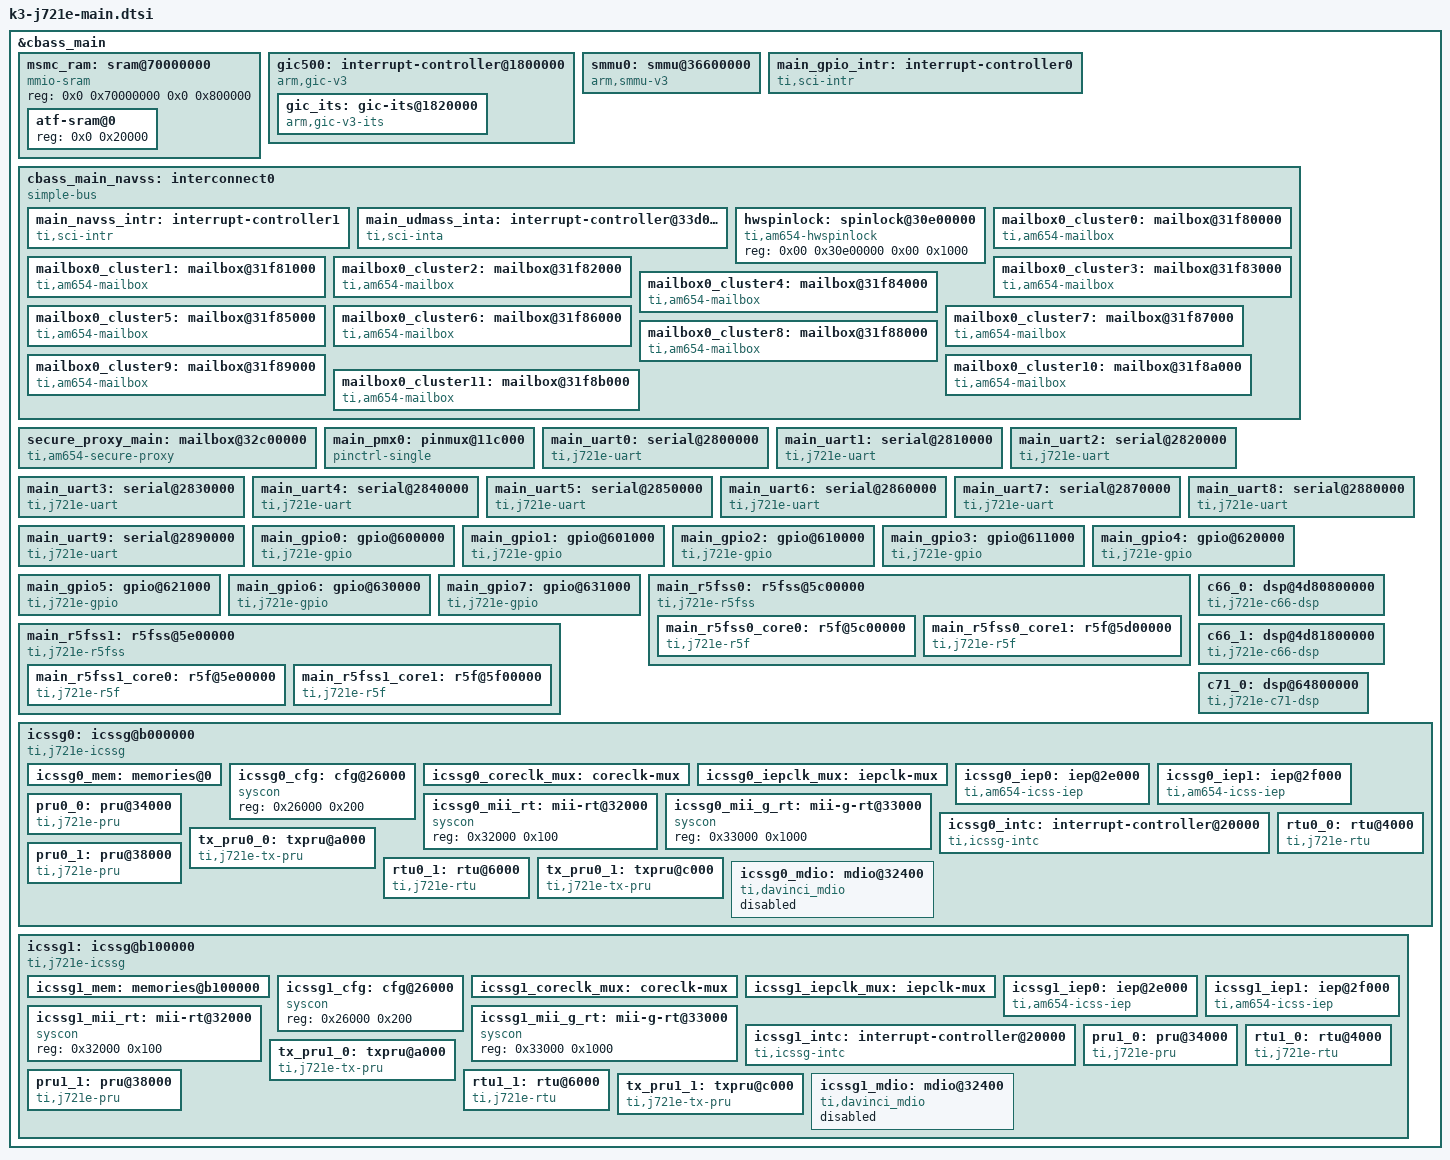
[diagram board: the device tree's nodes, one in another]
// SPDX-License-Identifier: GPL-2.0
/*
 * Device Tree Source for J721E SoC Family Main Domain peripherals
 *
 * Copyright (C) 2016-2019 Texas Instruments Incorporated - http://www.ti.com/
 */

&cbass_main {
	msmc_ram: sram@70000000 {
		compatible = "mmio-sram";
		reg = <0x0 0x70000000 0x0 0x800000>;
		#address-cells = <1>;
		#size-cells = <1>;
		ranges = <0x0 0x0 0x70000000 0x800000>;

		atf-sram@0 {
			reg = <0x0 0x20000>;
		};
	};

	gic500: interrupt-controller@1800000 {
		compatible = "arm,gic-v3";
		#address-cells = <2>;
		#size-cells = <2>;
		ranges;
		#interrupt-cells = <3>;
		interrupt-controller;
		reg = <0x00 0x01800000 0x00 0x10000>,	/* GICD */
		      <0x00 0x01900000 0x00 0x100000>;	/* GICR */

		/* vcpumntirq: virtual CPU interface maintenance interrupt */
		interrupts = <GIC_PPI 9 IRQ_TYPE_LEVEL_HIGH>;

		gic_its: gic-its@1820000 {
			compatible = "arm,gic-v3-its";
			reg = <0x00 0x01820000 0x00 0x10000>;
			socionext,synquacer-pre-its = <0x1000000 0x400000>;
			msi-controller;
			#msi-cells = <1>;
		};
	};

	smmu0: smmu@36600000 {
		compatible = "arm,smmu-v3";
		reg = <0x0 0x36600000 0x0 0x100000>;
		interrupt-parent = <&gic500>;
		interrupts = <GIC_SPI 772 IRQ_TYPE_EDGE_RISING>,
			     <GIC_SPI 768 IRQ_TYPE_EDGE_RISING>;
		interrupt-names = "eventq", "gerror";
		#iommu-cells = <1>;
	};

	main_gpio_intr: interrupt-controller0 {
		compatible = "ti,sci-intr";
		ti,intr-trigger-type = <1>;
		interrupt-controller;
		interrupt-parent = <&gic500>;
		#interrupt-cells = <2>;
		ti,sci = <&dmsc>;
		ti,sci-dst-id = <14>;
		ti,sci-rm-range-girq = <0x1>;
	};

	cbass_main_navss: interconnect0 {
		compatible = "simple-bus";
		#address-cells = <2>;
		#size-cells = <2>;
		ranges;

		main_navss_intr: interrupt-controller1 {
			compatible = "ti,sci-intr";
			ti,intr-trigger-type = <4>;
			interrupt-controller;
			interrupt-parent = <&gic500>;
			#interrupt-cells = <2>;
			ti,sci = <&dmsc>;
			ti,sci-dst-id = <14>;
			ti,sci-rm-range-girq = <0>, <2>;
		};

		main_udmass_inta: interrupt-controller@33d00000 {
			compatible = "ti,sci-inta";
			reg = <0x0 0x33d00000 0x0 0x100000>;
			interrupt-controller;
			interrupt-parent = <&main_navss_intr>;
			msi-controller;
			ti,sci = <&dmsc>;
			ti,sci-dev-id = <209>;
			ti,sci-rm-range-vint = <0xa>;
			ti,sci-rm-range-global-event = <0xd>;
		};

		hwspinlock: spinlock@30e00000 {
			compatible = "ti,am654-hwspinlock";
			reg = <0x00 0x30e00000 0x00 0x1000>;
			#hwlock-cells = <1>;
		};

		mailbox0_cluster0: mailbox@31f80000 {
			compatible = "ti,am654-mailbox";
			reg = <0x00 0x31f80000 0x00 0x200>;
			#mbox-cells = <1>;
			ti,mbox-num-users = <4>;
			ti,mbox-num-fifos = <16>;
			interrupt-parent = <&main_navss_intr>;
		};

		mailbox0_cluster1: mailbox@31f81000 {
			compatible = "ti,am654-mailbox";
			reg = <0x00 0x31f81000 0x00 0x200>;
			#mbox-cells = <1>;
			ti,mbox-num-users = <4>;
			ti,mbox-num-fifos = <16>;
			interrupt-parent = <&main_navss_intr>;
		};

		mailbox0_cluster2: mailbox@31f82000 {
			compatible = "ti,am654-mailbox";
			reg = <0x00 0x31f82000 0x00 0x200>;
			#mbox-cells = <1>;
			ti,mbox-num-users = <4>;
			ti,mbox-num-fifos = <16>;
			interrupt-parent = <&main_navss_intr>;
		};

		mailbox0_cluster3: mailbox@31f83000 {
			compatible = "ti,am654-mailbox";
			reg = <0x00 0x31f83000 0x00 0x200>;
			#mbox-cells = <1>;
			ti,mbox-num-users = <4>;
			ti,mbox-num-fifos = <16>;
			interrupt-parent = <&main_navss_intr>;
		};

		mailbox0_cluster4: mailbox@31f84000 {
			compatible = "ti,am654-mailbox";
			reg = <0x00 0x31f84000 0x00 0x200>;
			#mbox-cells = <1>;
			ti,mbox-num-users = <4>;
			ti,mbox-num-fifos = <16>;
			interrupt-parent = <&main_navss_intr>;
		};

		mailbox0_cluster5: mailbox@31f85000 {
			compatible = "ti,am654-mailbox";
			reg = <0x00 0x31f85000 0x00 0x200>;
			#mbox-cells = <1>;
			ti,mbox-num-users = <4>;
			ti,mbox-num-fifos = <16>;
			interrupt-parent = <&main_navss_intr>;
		};

		mailbox0_cluster6: mailbox@31f86000 {
			compatible = "ti,am654-mailbox";
			reg = <0x00 0x31f86000 0x00 0x200>;
			#mbox-cells = <1>;
			ti,mbox-num-users = <4>;
			ti,mbox-num-fifos = <16>;
			interrupt-parent = <&main_navss_intr>;
		};

		mailbox0_cluster7: mailbox@31f87000 {
			compatible = "ti,am654-mailbox";
			reg = <0x00 0x31f87000 0x00 0x200>;
			#mbox-cells = <1>;
			ti,mbox-num-users = <4>;
			ti,mbox-num-fifos = <16>;
			interrupt-parent = <&main_navss_intr>;
		};

		mailbox0_cluster8: mailbox@31f88000 {
			compatible = "ti,am654-mailbox";
			reg = <0x00 0x31f88000 0x00 0x200>;
			#mbox-cells = <1>;
			ti,mbox-num-users = <4>;
			ti,mbox-num-fifos = <16>;
			interrupt-parent = <&main_navss_intr>;
		};

		mailbox0_cluster9: mailbox@31f89000 {
			compatible = "ti,am654-mailbox";
			reg = <0x00 0x31f89000 0x00 0x200>;
			#mbox-cells = <1>;
			ti,mbox-num-users = <4>;
			ti,mbox-num-fifos = <16>;
			interrupt-parent = <&main_navss_intr>;
		};

		mailbox0_cluster10: mailbox@31f8a000 {
			compatible = "ti,am654-mailbox";
			reg = <0x00 0x31f8a000 0x00 0x200>;
			#mbox-cells = <1>;
			ti,mbox-num-users = <4>;
			ti,mbox-num-fifos = <16>;
			interrupt-parent = <&main_navss_intr>;
		};

		mailbox0_cluster11: mailbox@31f8b000 {
			compatible = "ti,am654-mailbox";
			reg = <0x00 0x31f8b000 0x00 0x200>;
			#mbox-cells = <1>;
			ti,mbox-num-users = <4>;
			ti,mbox-num-fifos = <16>;
			interrupt-parent = <&main_navss_intr>;
		};
	};

	secure_proxy_main: mailbox@32c00000 {
		compatible = "ti,am654-secure-proxy";
		#mbox-cells = <1>;
		reg-names = "target_data", "rt", "scfg";
		reg = <0x00 0x32c00000 0x00 0x100000>,
		      <0x00 0x32400000 0x00 0x100000>,
		      <0x00 0x32800000 0x00 0x100000>;
		interrupt-names = "rx_011";
		interrupts = <GIC_SPI 37 IRQ_TYPE_LEVEL_HIGH>;
	};

	main_pmx0: pinmux@11c000 {
		compatible = "pinctrl-single";
		/* Proxy 0 addressing */
		reg = <0x0 0x11c000 0x0 0x2b4>;
		#pinctrl-cells = <1>;
		pinctrl-single,register-width = <32>;
		pinctrl-single,function-mask = <0xffffffff>;
	};

	main_uart0: serial@2800000 {
		compatible = "ti,j721e-uart", "ti,am654-uart";
		reg = <0x00 0x02800000 0x00 0x100>;
		reg-shift = <2>;
		reg-io-width = <4>;
		interrupts = <GIC_SPI 192 IRQ_TYPE_LEVEL_HIGH>;
		clock-frequency = <48000000>;
		current-speed = <115200>;
		power-domains = <&k3_pds 146 TI_SCI_PD_EXCLUSIVE>;
		clocks = <&k3_clks 146 0>;
		clock-names = "fclk";
	};

	main_uart1: serial@2810000 {
		compatible = "ti,j721e-uart", "ti,am654-uart";
		reg = <0x00 0x02810000 0x00 0x100>;
		reg-shift = <2>;
		reg-io-width = <4>;
		interrupts = <GIC_SPI 193 IRQ_TYPE_LEVEL_HIGH>;
		clock-frequency = <48000000>;
		current-speed = <115200>;
		power-domains = <&k3_pds 278 TI_SCI_PD_EXCLUSIVE>;
		clocks = <&k3_clks 278 0>;
		clock-names = "fclk";
	};

	main_uart2: serial@2820000 {
		compatible = "ti,j721e-uart", "ti,am654-uart";
		reg = <0x00 0x02820000 0x00 0x100>;
		reg-shift = <2>;
		reg-io-width = <4>;
		interrupts = <GIC_SPI 194 IRQ_TYPE_LEVEL_HIGH>;
		clock-frequency = <48000000>;
		current-speed = <115200>;
		power-domains = <&k3_pds 279 TI_SCI_PD_EXCLUSIVE>;
		clocks = <&k3_clks 279 0>;
		clock-names = "fclk";
	};

	main_uart3: serial@2830000 {
		compatible = "ti,j721e-uart", "ti,am654-uart";
		reg = <0x00 0x02830000 0x00 0x100>;
		reg-shift = <2>;
		reg-io-width = <4>;
		interrupts = <GIC_SPI 195 IRQ_TYPE_LEVEL_HIGH>;
		clock-frequency = <48000000>;
		current-speed = <115200>;
		power-domains = <&k3_pds 280 TI_SCI_PD_EXCLUSIVE>;
		clocks = <&k3_clks 280 0>;
		clock-names = "fclk";
	};

	main_uart4: serial@2840000 {
		compatible = "ti,j721e-uart", "ti,am654-uart";
		reg = <0x00 0x02840000 0x00 0x100>;
		reg-shift = <2>;
		reg-io-width = <4>;
		interrupts = <GIC_SPI 196 IRQ_TYPE_LEVEL_HIGH>;
		clock-frequency = <48000000>;
		current-speed = <115200>;
		power-domains = <&k3_pds 281 TI_SCI_PD_EXCLUSIVE>;
		clocks = <&k3_clks 281 0>;
		clock-names = "fclk";
	};

	main_uart5: serial@2850000 {
		compatible = "ti,j721e-uart", "ti,am654-uart";
		reg = <0x00 0x02850000 0x00 0x100>;
		reg-shift = <2>;
		reg-io-width = <4>;
		interrupts = <GIC_SPI 197 IRQ_TYPE_LEVEL_HIGH>;
		clock-frequency = <48000000>;
		current-speed = <115200>;
		power-domains = <&k3_pds 282 TI_SCI_PD_EXCLUSIVE>;
		clocks = <&k3_clks 282 0>;
		clock-names = "fclk";
	};

	main_uart6: serial@2860000 {
		compatible = "ti,j721e-uart", "ti,am654-uart";
		reg = <0x00 0x02860000 0x00 0x100>;
		reg-shift = <2>;
		reg-io-width = <4>;
		interrupts = <GIC_SPI 198 IRQ_TYPE_LEVEL_HIGH>;
		clock-frequency = <48000000>;
		current-speed = <115200>;
		power-domains = <&k3_pds 283 TI_SCI_PD_EXCLUSIVE>;
		clocks = <&k3_clks 283 0>;
		clock-names = "fclk";
	};

	main_uart7: serial@2870000 {
		compatible = "ti,j721e-uart", "ti,am654-uart";
		reg = <0x00 0x02870000 0x00 0x100>;
		reg-shift = <2>;
		reg-io-width = <4>;
		interrupts = <GIC_SPI 199 IRQ_TYPE_LEVEL_HIGH>;
		clock-frequency = <48000000>;
		current-speed = <115200>;
		power-domains = <&k3_pds 284 TI_SCI_PD_EXCLUSIVE>;
		clocks = <&k3_clks 284 0>;
		clock-names = "fclk";
	};

	main_uart8: serial@2880000 {
		compatible = "ti,j721e-uart", "ti,am654-uart";
		reg = <0x00 0x02880000 0x00 0x100>;
		reg-shift = <2>;
		reg-io-width = <4>;
		interrupts = <GIC_SPI 248 IRQ_TYPE_LEVEL_HIGH>;
		clock-frequency = <48000000>;
		current-speed = <115200>;
		power-domains = <&k3_pds 285 TI_SCI_PD_EXCLUSIVE>;
		clocks = <&k3_clks 285 0>;
		clock-names = "fclk";
	};

	main_uart9: serial@2890000 {
		compatible = "ti,j721e-uart", "ti,am654-uart";
		reg = <0x00 0x02890000 0x00 0x100>;
		reg-shift = <2>;
		reg-io-width = <4>;
		interrupts = <GIC_SPI 249 IRQ_TYPE_LEVEL_HIGH>;
		clock-frequency = <48000000>;
		current-speed = <115200>;
		power-domains = <&k3_pds 286 TI_SCI_PD_EXCLUSIVE>;
		clocks = <&k3_clks 286 0>;
		clock-names = "fclk";
	};

	main_gpio0: gpio@600000 {
		compatible = "ti,j721e-gpio", "ti,keystone-gpio";
		reg = <0x0 0x00600000 0x0 0x100>;
		gpio-controller;
		#gpio-cells = <2>;
		interrupt-parent = <&main_gpio_intr>;
		interrupts = <105 0>, <105 1>, <105 2>, <105 3>,
			     <105 4>, <105 5>, <105 6>, <105 7>;
		interrupt-controller;
		#interrupt-cells = <2>;
		ti,ngpio = <128>;
		ti,davinci-gpio-unbanked = <0>;
		power-domains = <&k3_pds 105 TI_SCI_PD_EXCLUSIVE>;
		clocks = <&k3_clks 105 0>;
		clock-names = "gpio";
	};

	main_gpio1: gpio@601000 {
		compatible = "ti,j721e-gpio", "ti,keystone-gpio";
		reg = <0x0 0x00601000 0x0 0x100>;
		gpio-controller;
		#gpio-cells = <2>;
		interrupt-parent = <&main_gpio_intr>;
		interrupts = <106 0>, <106 1>, <106 2>;
		interrupt-controller;
		#interrupt-cells = <2>;
		ti,ngpio = <36>;
		ti,davinci-gpio-unbanked = <0>;
		power-domains = <&k3_pds 106 TI_SCI_PD_EXCLUSIVE>;
		clocks = <&k3_clks 106 0>;
		clock-names = "gpio";
	};

	main_gpio2: gpio@610000 {
		compatible = "ti,j721e-gpio", "ti,keystone-gpio";
		reg = <0x0 0x00610000 0x0 0x100>;
		gpio-controller;
		#gpio-cells = <2>;
		interrupt-parent = <&main_gpio_intr>;
		interrupts = <107 0>, <107 1>, <107 2>, <107 3>,
			     <107 4>, <107 5>, <107 6>, <107 7>;
		interrupt-controller;
		#interrupt-cells = <2>;
		ti,ngpio = <128>;
		ti,davinci-gpio-unbanked = <0>;
		power-domains = <&k3_pds 107 TI_SCI_PD_EXCLUSIVE>;
		clocks = <&k3_clks 107 0>;
		clock-names = "gpio";
	};

	main_gpio3: gpio@611000 {
		compatible = "ti,j721e-gpio", "ti,keystone-gpio";
		reg = <0x0 0x00611000 0x0 0x100>;
		gpio-controller;
		#gpio-cells = <2>;
		interrupt-parent = <&main_gpio_intr>;
		interrupts = <108 0>, <108 1>, <108 2>;
		interrupt-controller;
		#interrupt-cells = <2>;
		ti,ngpio = <36>;
		ti,davinci-gpio-unbanked = <0>;
		power-domains = <&k3_pds 108 TI_SCI_PD_EXCLUSIVE>;
		clocks = <&k3_clks 108 0>;
		clock-names = "gpio";
	};

	main_gpio4: gpio@620000 {
		compatible = "ti,j721e-gpio", "ti,keystone-gpio";
		reg = <0x0 0x00620000 0x0 0x100>;
		gpio-controller;
		#gpio-cells = <2>;
		interrupt-parent = <&main_gpio_intr>;
		interrupts = <109 0>, <109 1>, <109 2>, <109 3>,
			     <109 4>, <109 5>, <109 6>, <109 7>;
		interrupt-controller;
		#interrupt-cells = <2>;
		ti,ngpio = <128>;
		ti,davinci-gpio-unbanked = <0>;
		power-domains = <&k3_pds 109 TI_SCI_PD_EXCLUSIVE>;
		clocks = <&k3_clks 109 0>;
		clock-names = "gpio";
	};

	main_gpio5: gpio@621000 {
		compatible = "ti,j721e-gpio", "ti,keystone-gpio";
		reg = <0x0 0x00621000 0x0 0x100>;
		gpio-controller;
		#gpio-cells = <2>;
		interrupt-parent = <&main_gpio_intr>;
		interrupts = <110 0>, <110 1>, <110 2>;
		interrupt-controller;
		#interrupt-cells = <2>;
		ti,ngpio = <36>;
		ti,davinci-gpio-unbanked = <0>;
		power-domains = <&k3_pds 110 TI_SCI_PD_EXCLUSIVE>;
		clocks = <&k3_clks 110 0>;
		clock-names = "gpio";
	};

	main_gpio6: gpio@630000 {
		compatible = "ti,j721e-gpio", "ti,keystone-gpio";
		reg = <0x0 0x00630000 0x0 0x100>;
		gpio-controller;
		#gpio-cells = <2>;
		interrupt-parent = <&main_gpio_intr>;
		interrupts = <111 0>, <111 1>, <111 2>, <111 3>,
			     <111 4>, <111 5>, <111 6>, <111 7>;
		interrupt-controller;
		#interrupt-cells = <2>;
		ti,ngpio = <128>;
		ti,davinci-gpio-unbanked = <0>;
		power-domains = <&k3_pds 111 TI_SCI_PD_EXCLUSIVE>;
		clocks = <&k3_clks 111 0>;
		clock-names = "gpio";
	};

	main_gpio7: gpio@631000 {
		compatible = "ti,j721e-gpio", "ti,keystone-gpio";
		reg = <0x0 0x00631000 0x0 0x100>;
		gpio-controller;
		#gpio-cells = <2>;
		interrupt-parent = <&main_gpio_intr>;
		interrupts = <112 0>, <112 1>, <112 2>;
		interrupt-controller;
		#interrupt-cells = <2>;
		ti,ngpio = <36>;
		ti,davinci-gpio-unbanked = <0>;
		power-domains = <&k3_pds 112 TI_SCI_PD_EXCLUSIVE>;
		clocks = <&k3_clks 112 0>;
		clock-names = "gpio";
	};

	main_r5fss0: r5fss@5c00000 {
		compatible = "ti,j721e-r5fss";
		lockstep-mode = <0>;
		#address-cells = <1>;
		#size-cells = <1>;
		ranges = <0x5c00000 0x00 0x5c00000 0x20000>,
			 <0x5d00000 0x00 0x5d00000 0x20000>;
		power-domains = <&k3_pds 243 TI_SCI_PD_EXCLUSIVE>;

		main_r5fss0_core0: r5f@5c00000 {
			compatible = "ti,j721e-r5f";
			reg = <0x5c00000 0x00008000>,
			      <0x5c10000 0x00008000>;
			reg-names = "atcm", "btcm";
			ti,sci = <&dmsc>;
			ti,sci-dev-id = <245>;
			ti,sci-proc-ids = <0x06 0xFF>;
			resets = <&k3_reset 245 1>;
			firmware-name = "j7-main-r5f0_0-fw";
			atcm-enable = <1>;
			btcm-enable = <1>;
			loczrama = <1>;
		};

		main_r5fss0_core1: r5f@5d00000 {
			compatible = "ti,j721e-r5f";
			reg = <0x5d00000 0x00008000>,
			      <0x5d10000 0x00008000>;
			reg-names = "atcm", "btcm";
			ti,sci = <&dmsc>;
			ti,sci-dev-id = <246>;
			ti,sci-proc-ids = <0x07 0xFF>;
			resets = <&k3_reset 246 1>;
			firmware-name = "j7-main-r5f0_1-fw";
			atcm-enable = <1>;
			btcm-enable = <1>;
			loczrama = <1>;
		};
	};

	main_r5fss1: r5fss@5e00000 {
		compatible = "ti,j721e-r5fss";
		lockstep-mode = <0>;
		#address-cells = <1>;
		#size-cells = <1>;
		ranges = <0x5e00000 0x00 0x5e00000 0x20000>,
			 <0x5f00000 0x00 0x5f00000 0x20000>;
		power-domains = <&k3_pds 244 TI_SCI_PD_EXCLUSIVE>;

		main_r5fss1_core0: r5f@5e00000 {
			compatible = "ti,j721e-r5f";
			reg = <0x5e00000 0x00008000>,
			      <0x5e10000 0x00008000>;
			reg-names = "atcm", "btcm";
			ti,sci = <&dmsc>;
			ti,sci-dev-id = <247>;
			ti,sci-proc-ids = <0x08 0xFF>;
			resets = <&k3_reset 247 1>;
			firmware-name = "j7-main-r5f1_0-fw";
			atcm-enable = <1>;
			btcm-enable = <1>;
			loczrama = <1>;
		};

		main_r5fss1_core1: r5f@5f00000 {
			compatible = "ti,j721e-r5f";
			reg = <0x5f00000 0x00008000>,
			      <0x5f10000 0x00008000>;
			reg-names = "atcm", "btcm";
			ti,sci = <&dmsc>;
			ti,sci-dev-id = <248>;
			ti,sci-proc-ids = <0x09 0xFF>;
			resets = <&k3_reset 248 1>;
			firmware-name = "j7-main-r5f1_1-fw";
			atcm-enable = <1>;
			btcm-enable = <1>;
			loczrama = <1>;
		};
	};

	c66_0: dsp@4d80800000 {
		compatible = "ti,j721e-c66-dsp";
		reg = <0x4d 0x80800000 0x00 0x00048000>,
		      <0x4d 0x80e00000 0x00 0x00008000>,
		      <0x4d 0x80f00000 0x00 0x00008000>;
		reg-names = "l2sram", "l1pram", "l1dram";
		ti,sci = <&dmsc>;
		ti,sci-dev-id = <142>;
		ti,sci-proc-ids = <0x03 0xFF>;
		resets = <&k3_reset 142 1>;
		firmware-name = "j7-c66_0-fw";
	};

	c66_1: dsp@4d81800000 {
		compatible = "ti,j721e-c66-dsp";
		reg = <0x4d 0x81800000 0x00 0x00048000>,
		      <0x4d 0x81e00000 0x00 0x00008000>,
		      <0x4d 0x81f00000 0x00 0x00008000>;
		reg-names = "l2sram", "l1pram", "l1dram";
		ti,sci = <&dmsc>;
		ti,sci-dev-id = <143>;
		ti,sci-proc-ids = <0x04 0xFF>;
		resets = <&k3_reset 143 1>;
		firmware-name = "j7-c66_1-fw";
	};

	c71_0: dsp@64800000 {
		compatible = "ti,j721e-c71-dsp";
		reg = <0x00 0x64800000 0x00 0x00080000>,
		      <0x00 0x64e00000 0x00 0x0000c000>;
		reg-names = "l2sram", "l1dram";
		ti,sci = <&dmsc>;
		ti,sci-dev-id = <15>;
		ti,sci-proc-ids = <0x30 0xFF>;
		resets = <&k3_reset 15 1>;
		firmware-name = "j7-c71_0-fw";
	};

	icssg0: icssg@b000000 {
		compatible = "ti,j721e-icssg";
		reg = <0x00 0xb000000 0x00 0x80000>;
		power-domains = <&k3_pds 119 TI_SCI_PD_EXCLUSIVE>;
		#address-cells = <1>;
		#size-cells = <1>;
		ranges = <0x0 0x00 0x0b000000 0x100000>;
		dma-ranges;

		icssg0_mem: memories@0 {
			reg = <0x0 0x2000>,
			      <0x2000 0x2000>,
			      <0x10000 0x10000>;
			reg-names = "dram0", "dram1",
				    "shrdram2";
		};

		icssg0_cfg: cfg@26000 {
			compatible = "syscon";
			reg = <0x26000 0x200>;
		};

		icssg0_coreclk_mux: coreclk-mux {
			#clock-cells = <0>;
			clocks = <&k3_clks 119 24>, /* icssg0_core_clk */
				 <&k3_clks 119 1>;  /* icssg0_iclk */
			assigned-clocks = <&icssg0_coreclk_mux>;
			assigned-clock-parents = <&k3_clks 119 1>;
		};

		icssg0_iepclk_mux: iepclk-mux {
			#clock-cells = <0>;
			clocks = <&k3_clks 119 3>,	/* icssg0_iep_clk */
				 <&icssg0_coreclk_mux>;	/* core_clk */
			assigned-clocks = <&icssg0_iepclk_mux>;
			assigned-clock-parents = <&icssg0_coreclk_mux>;
		};

		icssg0_iep0: iep@2e000 {
			compatible = "ti,am654-icss-iep";
			reg = <0x2e000 0x1000>;
			clocks = <&icssg0_iepclk_mux>;
		};

		icssg0_iep1: iep@2f000 {
			compatible = "ti,am654-icss-iep";
			reg = <0x2f000 0x1000>;
			clocks = <&icssg0_iepclk_mux>;
		};

		icssg0_mii_rt: mii-rt@32000 {
			compatible = "syscon";
			reg = <0x32000 0x100>;
		};

		icssg0_mii_g_rt: mii-g-rt@33000 {
			compatible = "syscon";
			reg = <0x33000 0x1000>;
		};

		icssg0_intc: interrupt-controller@20000 {
			compatible = "ti,icssg-intc";
			reg = <0x20000 0x2000>;
			interrupt-controller;
			#interrupt-cells = <1>;
			interrupts = <GIC_SPI 254 IRQ_TYPE_LEVEL_HIGH>,
				     <GIC_SPI 255 IRQ_TYPE_LEVEL_HIGH>,
				     <GIC_SPI 256 IRQ_TYPE_LEVEL_HIGH>,
				     <GIC_SPI 257 IRQ_TYPE_LEVEL_HIGH>,
				     <GIC_SPI 258 IRQ_TYPE_LEVEL_HIGH>,
				     <GIC_SPI 259 IRQ_TYPE_LEVEL_HIGH>,
				     <GIC_SPI 260 IRQ_TYPE_LEVEL_HIGH>,
				     <GIC_SPI 261 IRQ_TYPE_LEVEL_HIGH>;
			interrupt-names = "host_intr0", "host_intr1",
					  "host_intr2", "host_intr3",
					  "host_intr4", "host_intr5",
					  "host_intr6", "host_intr7";
			ti,irqs-shared = /bits/ 8 <0 1 2 3 4 5 6 7>;
		};

		pru0_0: pru@34000 {
			compatible = "ti,j721e-pru";
			reg = <0x34000 0x3000>,
			      <0x22000 0x100>,
			      <0x22400 0x100>;
			reg-names = "iram", "control", "debug";
			firmware-name = "j7-pru0_0-fw";
			interrupt-parent = <&icssg0_intc>;
			interrupts = <16>, <17>;
			interrupt-names = "vring", "kick";
		};

		rtu0_0: rtu@4000 {
			compatible = "ti,j721e-rtu";
			reg = <0x4000 0x2000>,
			      <0x23000 0x100>,
			      <0x23400 0x100>;
			reg-names = "iram", "control", "debug";
			firmware-name = "j7-rtu0_0-fw";
			interrupt-parent = <&icssg0_intc>;
			interrupts = <20>, <21>;
			interrupt-names = "vring", "kick";
		};

		tx_pru0_0: txpru@a000 {
			compatible = "ti,j721e-tx-pru";
			reg = <0xa000 0x1800>,
			      <0x25000 0x100>,
			      <0x25400 0x100>;
			reg-names = "iram", "control", "debug";
			firmware-name = "j7-txpru0_0-fw";
		};

		pru0_1: pru@38000 {
			compatible = "ti,j721e-pru";
			reg = <0x38000 0x3000>,
			      <0x24000 0x100>,
			      <0x24400 0x100>;
			reg-names = "iram", "control", "debug";
			firmware-name = "j7-pru0_1-fw";
			interrupt-parent = <&icssg0_intc>;
			interrupts = <18>, <19>;
			interrupt-names = "vring", "kick";
		};

		rtu0_1: rtu@6000 {
			compatible = "ti,j721e-rtu";
			reg = <0x6000 0x2000>,
			      <0x23800 0x100>,
			      <0x23c00 0x100>;
			reg-names = "iram", "control", "debug";
			firmware-name = "j7-rtu0_1-fw";
			interrupt-parent = <&icssg0_intc>;
			interrupts = <22>, <23>;
			interrupt-names = "vring", "kick";
		};

		tx_pru0_1: txpru@c000 {
			compatible = "ti,j721e-tx-pru";
			reg = <0xc000 0x1800>,
			      <0x25800 0x100>,
			      <0x25c00 0x100>;
			reg-names = "iram", "control", "debug";
			firmware-name = "j7-txpru0_1-fw";
		};

		icssg0_mdio: mdio@32400 {
			compatible = "ti,davinci_mdio";
			reg = <0x32400 0x100>;
			clocks = <&k3_clks 119 1>;
			clock-names = "fck";
			#address-cells = <1>;
			#size-cells = <0>;
			bus_freq = <1000000>;
			status = "disabled";
		};
	};

	icssg1: icssg@b100000 {
		compatible = "ti,j721e-icssg";
		reg = <0x00 0xb100000 0x00 0x80000>;
		power-domains = <&k3_pds 120 TI_SCI_PD_EXCLUSIVE>;
		#address-cells = <1>;
		#size-cells = <1>;
		ranges = <0x0 0x00 0x0b100000 0x100000>;
		dma-ranges;

		icssg1_mem: memories@b100000 {
			reg = <0x0 0x2000>,
			      <0x2000 0x2000>,
			      <0x10000 0x10000>;
			reg-names = "dram0", "dram1",
				    "shrdram2";
		};

		icssg1_cfg: cfg@26000 {
			compatible = "syscon";
			reg = <0x26000 0x200>;
		};

		icssg1_coreclk_mux: coreclk-mux {
			#clock-cells = <0>;
			clocks = <&k3_clks 120 54>, /* icssg1_core_clk */
				 <&k3_clks 120 4>;  /* icssg1_iclk */
			assigned-clocks = <&icssg1_coreclk_mux>;
			assigned-clock-parents = <&k3_clks 120 4>;
		};

		icssg1_iepclk_mux: iepclk-mux {
			#clock-cells = <0>;
			clocks = <&k3_clks 120 9>,	/* icssg1_iep_clk */
				 <&icssg1_coreclk_mux>;	/* core_clk */
			assigned-clocks = <&icssg1_iepclk_mux>;
			assigned-clock-parents = <&icssg1_coreclk_mux>;
		};

		icssg1_iep0: iep@2e000 {
			compatible = "ti,am654-icss-iep";
			reg = <0x2e000 0x1000>;
			clocks = <&icssg1_iepclk_mux>;
		};

		icssg1_iep1: iep@2f000 {
			compatible = "ti,am654-icss-iep";
			reg = <0x2f000 0x1000>;
			clocks = <&icssg1_iepclk_mux>;
		};

		icssg1_mii_rt: mii-rt@32000 {
			compatible = "syscon";
			reg = <0x32000 0x100>;
		};

		icssg1_mii_g_rt: mii-g-rt@33000 {
			compatible = "syscon";
			reg = <0x33000 0x1000>;
		};

		icssg1_intc: interrupt-controller@20000 {
			compatible = "ti,icssg-intc";
			reg = <0x20000 0x2000>;
			interrupt-controller;
			#interrupt-cells = <1>;
			interrupts = <GIC_SPI 262 IRQ_TYPE_LEVEL_HIGH>,
				     <GIC_SPI 263 IRQ_TYPE_LEVEL_HIGH>,
				     <GIC_SPI 264 IRQ_TYPE_LEVEL_HIGH>,
				     <GIC_SPI 265 IRQ_TYPE_LEVEL_HIGH>,
				     <GIC_SPI 266 IRQ_TYPE_LEVEL_HIGH>,
				     <GIC_SPI 267 IRQ_TYPE_LEVEL_HIGH>,
				     <GIC_SPI 268 IRQ_TYPE_LEVEL_HIGH>,
				     <GIC_SPI 269 IRQ_TYPE_LEVEL_HIGH>;
			interrupt-names = "host_intr0", "host_intr1",
					  "host_intr2", "host_intr3",
					  "host_intr4", "host_intr5",
					  "host_intr6", "host_intr7";
			ti,irqs-shared = /bits/ 8 <0 1 2 3 4 5 6 7>;
		};

		pru1_0: pru@34000 {
			compatible = "ti,j721e-pru";
			reg = <0x34000 0x4000>,
			      <0x22000 0x100>,
			      <0x22400 0x100>;
			reg-names = "iram", "control", "debug";
			firmware-name = "j7-pru1_0-fw";
			interrupt-parent = <&icssg1_intc>;
			interrupts = <16>, <17>;
			interrupt-names = "vring", "kick";
		};

		rtu1_0: rtu@4000 {
			compatible = "ti,j721e-rtu";
			reg = <0x4000 0x2000>,
			      <0x23000 0x100>,
			      <0x23400 0x100>;
			reg-names = "iram", "control", "debug";
			firmware-name = "j7-rtu1_0-fw";
			interrupt-parent = <&icssg1_intc>;
			interrupts = <20>, <21>;
			interrupt-names = "vring", "kick";
		};

		tx_pru1_0: txpru@a000 {
			compatible = "ti,j721e-tx-pru";
			reg = <0xa000 0x1800>,
			      <0x25000 0x100>,
			      <0x25400 0x100>;
			reg-names = "iram", "control", "debug";
			firmware-name = "j7-txpru1_0-fw";
		};

		pru1_1: pru@38000 {
			compatible = "ti,j721e-pru";
			reg = <0x38000 0x4000>,
			      <0x24000 0x100>,
			      <0x24400 0x100>;
			reg-names = "iram", "control", "debug";
			firmware-name = "j7-pru1_1-fw";
			interrupt-parent = <&icssg1_intc>;
			interrupts = <18>, <19>;
			interrupt-names = "vring", "kick";
		};

		rtu1_1: rtu@6000 {
			compatible = "ti,j721e-rtu";
			reg = <0x6000 0x2000>,
			      <0x23800 0x100>,
			      <0x23c00 0x100>;
			reg-names = "iram", "control", "debug";
			firmware-name = "j7-rtu1_1-fw";
			interrupt-parent = <&icssg1_intc>;
			interrupts = <22>, <23>;
			interrupt-names = "vring", "kick";
		};

		tx_pru1_1: txpru@c000 {
			compatible = "ti,j721e-tx-pru";
			reg = <0xc000 0x1800>,
			      <0x25800 0x100>,
			      <0x25c00 0x100>;
			reg-names = "iram", "control", "debug";
			firmware-name = "j7-txpru1_1-fw";
		};

		icssg1_mdio: mdio@32400 {
			compatible = "ti,davinci_mdio";
			reg = <0x32400 0x100>;
			clocks = <&k3_clks 120 4>;
			clock-names = "fck";
			#address-cells = <1>;
			#size-cells = <0>;
			bus_freq = <1000000>;
			status = "disabled";
		};
	};
};
